# CYBLE_416045_02 register map
File version: 0.1
Registers are 32-bit, read-write, no defined reset value unless marked. A register's access mark holds for its fields unless they carry their own. Offsets are from the block's base; [hi:lo] are bit positions; 'fields as' and 'values as' point back to an identical list.

## IDAC
Base 0x00000000
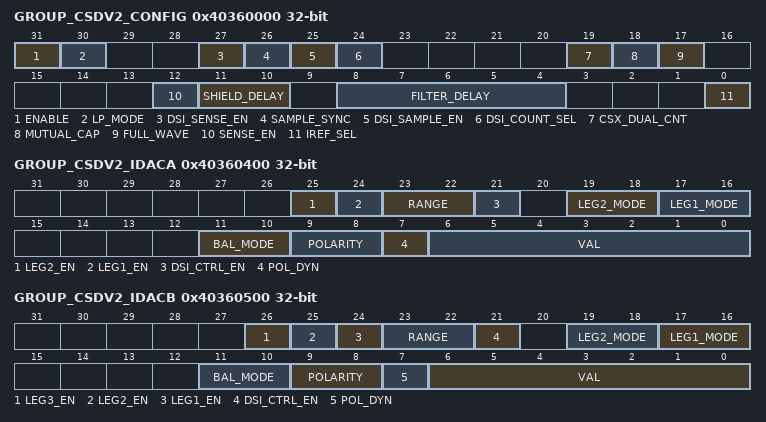
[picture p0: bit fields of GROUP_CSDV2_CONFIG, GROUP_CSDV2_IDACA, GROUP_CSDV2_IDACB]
0x40360000 GROUP_CSDV2_CONFIG — Configuration and Control
  [31] ENABLE — Master enable of the CSDv2 IP. Must be set to 1 for any CSDv2, ADC or IDAC operation to function.?When 0 all analog components will be off and all switches will be open.
  [30] LP_MODE — Select the power mode for the CSD components (REFGEN, AMBUF, CSDCMP, HSCMP):?0: High Power mode?1: Low Power mode
  [27] DSI_SENSE_EN — Enables the use of the dsi_sense_in input instead of the internally generated modulation signal to drive csd_sense and csd_shield signals.
  [26] SAMPLE_SYNC — Enables double synchronizing of sample input from DSI (only relevant when DSI_SAMPLE_EN=1).
  [25] DSI_SAMPLE_EN — Enables the use of the dsi_sample_in input instead of the comparator output to strobe COUNTER.
  [24] DSI_COUNT_SEL — Select what to output on the dsi_count bus.
    0=CSD_RESULT (depending on the dsi_count_val_sel input either output RESULT_VAL1.VALUE (0) or RESULT_VAL2.VALUE (1) on the dsi_count bus. Note that dsi_count_val_sel is not synchronized, i.e. it controls the mux combinatorially.); 1=ADC_RESULT (output ADC_RES.VIN_CNT on the dsi_count bus)
  [19] CSX_DUAL_CNT — Enable the use of two counters for MUTUAL cap sensing mode (CSX), do not use when MUTUAL_CAP=0
    0=ONE (Use one counter for both phases (source and sink).); 1=TWO (Use two counters, separate count for when csd_sense is high and when csd_sense is low.)
  [18] MUTUAL_CAP — Enables mutual cap sensing mode
    0=SELFCAP (Self-cap mode (configure sense line as CSD_SENSE)); 1=MUTUALCAP (Mutual-cap mode (configure Tx line as CSD_SENSE, inverted Tx line as CSD_SHIELD and Rx Line as AMUXA). In this mode the polarity bit of the IDAC is controlled by csd_sense.)
  [17] FULL_WAVE — Enables full wave cap sensing mode
    0=HALFWAVE (Half Wave mode (normal).?In this mode the comparator always trips in the same direction (positive or negative edge) and the same Vref, i.e. no polarity change.); 1=FULLWAVE (Full Wave mode.?In this mode the comparator trips in opposite direction and with different Vref in each phase, i.e. the polarity flips.)
  [12] SENSE_EN — Enables the sense modulator output. ?0: all switches, static or dynamic, are open and IDAC in CSD mode is off?1: switches and IDAC can be closed/on as per MMIO setting and CSD sequencer.
  [11:10] SHIELD_DELAY — Selects the delay by which csd_shield is delayed relative to csd_sense.
    0=OFF (Delay line is off, csd_shield=csd_sense); 1=D5NS (Introduces a 5ns delay (typ)); 2=D10NS (Introduces a 10ns delay (typ)); 3=D20NS (Introduces a 20ns delay (typ))
  [8:4] FILTER_DELAY — This value determines the number of cycles that the digital filter makes the CSDCMP output ignored while the counter counts and IDAC is on. ?When set to 0 the digital filter is off. When set to any other value the ignoring will last for FILTER_DELAY clk_csd cycles after the start of each measurement and from the first comparator trip to the end of each measurement.
  [0] IREF_SEL — Select Iref supply.
    0=IREF_SRSS (select SRSS Iref (default)); 1=IREF_PASS (select PASS.AREF Iref, only available if PASS IP is on the chip.)
0x40360400 GROUP_CSDV2_IDACA — IDACA Configuration
  [25] LEG2_EN — output enable for leg 2 to CSDBUSA
  [24] LEG1_EN — output enable for leg 1 to CSDBUSA
  [23:22] RANGE — IDAC multiplier
    0=IDAC_LO (1 LSB = 37.5 nA); 1=IDAC_MED (1 LSB = 300 nA); 2=IDAC_HI (1 LSB = 2400 nA)
  [21] DSI_CTRL_EN — Mix DSI inputs with MMIO controls or not (before getting mixed with CSD controls if enabled).?0: no DSI control ? IDACA_POLARITY = IDACA.POLARITY ? IDACA_LEG1_EN = IDACA.LEG1_EN ? IDACA_LEG2_EN = IDACA.LEG2_EN ?1: Mix MMIO with DSI control? IDACA_POLARITY = IDACA.POLARITY EXOR dsi_idaca_pol? IDACA_LEG1_EN = IDACA.LEG1_EN AND dsi_idaca_leg1_en ? IDACA_LEG2_EN = IDACA.LEG2_EN AND dsi_idaca_leg2_en
  [19:18] LEG2_MODE — Controls the usage mode of LEG2
    0=GP_STATIC (General Purpose static mode: LEG2 is controlled by MMIO and optionally mixed with DSI (see DSI_CTRL_EN). No shunting is used, this saves power when off but also any on/off switching will take longer.); 1=GP (General Purpose dynamic mode: LEG2 is controlled by MMIO and optionally mixed with DSI (see DSI_CTRL_EN). Shunting is used, so on/off switching is faster, but power is wasted when the leg is disabled.); 2=CSD_STATIC (CSD static mode: LEG2 can only be on when the CSD Sequencer is in the Sample_init or Sample_norm state. In those states LEG2 is controlled by LEG2_EN, csd_sense and the CSD configuration. Polarity is controlled by the CSD configuration and operation. In addition leg2 enable and polarity can optionally be mixed with DSI (see DSI_CTRL_EN). No shunting is used, this saves power when off but also any on/off switching will take longer.); 3=CSD (CSD dynamic mode: LEG2 can only be on when the CSD Sequencer is in the Sample_init or Sample_norm state. In those states LEG2 is controlled by LEG2_EN, the CSD configuration, csd_sense and the flopped CSDCMP output (CSDCMP_OUT_FF). In addition leg2 enable can optionally be mixed with DSI (see DSI_CTRL_EN). Shunting is used, so on/off switching is faster, but power is wasted when the leg is disabled.)
  [17:16] LEG1_MODE — Controls the usage mode of LEG1 and the Polarity bit
    0=GP_STATIC (General Purpose static mode: LEG1 and POLARITY are controlled by MMIO and optionally mixed with DSI (see DSI_CTRL_EN). No shunting is used, this saves power when off but also any on/off switching will take longer.); 1=GP (General Purpose dynamic mode: LEG1 and POLARITY are controlled by MMIO and optionally mixed with DSI (see DSI_CTRL_EN). Shunting is used, so on/off switching is faster, but power is wasted when the leg is disabled.); 2=CSD_STATIC (CSD static mode: LEG1 can only be on when the CSD Sequencer is in the Sample_init or Sample_norm state. In those states LEG1 is controlled by LEG1_EN, csd_sense and the CSD configuration. Polarity is controlled by the CSD configuration and operation. In addition leg1 enable and polarity can optionally be mixed with DSI (see DSI_CTRL_EN). No shunting is used, this saves power when off but also any on/off switching will take longer.); 3=CSD (CSD dynamic mode: LEG1 can only be on when the CSD Sequencer is in the Sample_init or Sample_norm state. In thoses states LEG1 is controlled by LEG1_EN, the CSD configuration, csd_sense and the flopped CSDCMP output (CSDCMP_OUT_FF). Polarity is controlled by the CSD configuration and operation. In addition leg1 enable and polarity can optionally be mixed with DSI (see DSI_CTRL_EN). Shunting is used, so on/off switching is faster, but power is wasted when the leg is disabled.)
  [11:10] BAL_MODE — Balancing mode: only applies to legs configured as CSD.
    0=FULL (enabled from start of Phi2 until disabled by CSDCMP. Intended usage: legacy CSD for balancing over a full csd_sense period (non-overlap should be turned off)); 1=PHI1 (enabled from start of Phi1 and disabled by CSDCMP or at end of Phi1. Enables dual IDAC CSX or Full-Wave, one for sourcing and the other for sinking.); 2=PHI2 (enabled from start of Phi2 and disabled by CSDCMP or at end of Phi2. Intended usage: CSD Low EMI or dual IDAC CSX or Full-Wave.); 3=PHI1_2 (enabled from start of both Phi1 and Phi2 and disabled by CSDCMP or at end of Phi1 or Phi2 (if non-overlap enabled). Intended usage: single IDAC CSX, or Full-Wave.)
  [9:8] POLARITY — Selects the polarity of the IDAC (sensing operation). Normally the actual polarity depends on this bit, optionally mixed with DSI (see DSI_CTRL_EN) and if LEG1_MODE==CSD also mixed with the CSD configuration and operation. However in mutual cap mode with one IDAC (config.mutual_cap=1 & config.csx_dual_idac=0) the polarity of the IDAC is controlled by csd_sense.
    0=VSSA_SRC (Normal: switch between Vssa and Cmod. For non-CSD application, IDAC will source current.); 1=VDDA_SNK (Inverted: switch between Vdda and Cmod. For non-CSD application, IDAC will sink current.); 2=SENSE (The polarity of the IDAC will follow the csd_sense signal (POL_DYN bit should be set too). The intended usage is for CSX using a single IDAC.); 3=SENSE_INV (The polarity of the IDAC will follow the inverted csd_sense signal (POL_DYN bit should be set too). The intended usage is for CSX using a single IDAC.)
  [7] POL_DYN — Polarity is dynamic, this bit does not influence the logic in the SoftIP, it only goes to the HardIP.
    0=STATIC (Static polarity. Polarity is expected to be stable, so to save power this avoids the shunting of the unused polarity, at the expense of response time.); 1=DYNAMIC (Dynamic polarity. Polarity is expected to change frequently (e.g. invert after every csd_sense phase), so to improve response time this keeps the shunt of the unused polarity on at the expense of power.)
  [6:0] VAL — Current value setting for this IDAC (7 bits).
0x40360500 GROUP_CSDV2_IDACB — IDACB Configuration
  [26] LEG3_EN — output enable for leg3 to CSDBUSC, only allowed when RANGE = IDAC_LO. When this bit is set both other legs should be off.?Note that leg3 can only be used for ADC mode, not GP mode. Which means that leg3 can only be on when the ADC Sequencer is in the ADC_measure or Calib_measure state. In those states leg3 is controlled by the ADC configuration and the HSCMP output. In addition this leg3 enable bit can optionally be mixed with DSI (see DSI_CTRL_EN).?When LEG3_EN=1 also the IDACB polarity is controlled by the ADC sequencer.
  [25] LEG2_EN — output enable for leg 2 to CSDBUSB or CSDBUSA
  [24] LEG1_EN — output enable for leg 1 to CSDBUSB or CSDBUSA
  [23:22] RANGE — IDAC multiplier
    values as GROUP_CSDV2_IDACA.RANGE
  [21] DSI_CTRL_EN — Mix DSI inputs with MMIO controls or not (before getting mixed with CSD controls if enabled)?0: no DSI control? IDACB_POLARITY = IDACB.POLARITY ? IDACB_LEG1_EN = IDACB.LEG1_EN ? IDACB_LEG2_EN = IDACB.LEG2_EN ? IDACB_LEG3_EN = IDACB.LEG3_EN ?1: Mix MMIO with DSI control? IDACB_POLARITY = IDACB.POLARITY EXOR dsi_idacb_pol? IDACB_LEG1_EN = IDACB.LEG1_EN AND dsi_idacb_leg1_en ? IDACB_LEG2_EN = IDACB.LEG2_EN AND dsi_idacb_leg2_en ? IDACB_LEG3_EN = IDACB.LEG3_EN AND dsi_idacb_leg3_en
  [19:18] LEG2_MODE — Controls the usage mode of LEG2
    0=GP_STATIC (same as corresponding IDACA.LEG2_MODE); 1=GP (same as corresponding IDACA.LEG2_MODE); 2=CSD_STATIC (same as corresponding IDACA.LEG2_MODE); 3=CSD (same as corresponding IDACA.LEG2_MODE)
  [17:16] LEG1_MODE — Controls the usage mode of LEG1 and the Polarity bit
    0=GP_STATIC (same as corresponding IDACA.LEG1_MODE); 1=GP (same as corresponding IDACA.LEG1_MODE); 2=CSD_STATIC (same as corresponding IDACA.LEG1_MODE); 3=CSD (same as corresponding IDACA.LEG1_MODE)
  [11:10] BAL_MODE — same as corresponding IDACA Balancing mode
    0=FULL (same as corresponding IDACA Balancing mode); 1=PHI1 (same as corresponding IDACA Balancing mode); 2=PHI2 (same as corresponding IDACA Balancing mode); 3=PHI1_2 (same as corresponding IDACA Balancing mode)
  [9:8] POLARITY — Selects the polarity of the IDAC (sensing operation). Normally the actual polarity depends on this bit, optionally mixed with DSI (see DSI_CTRL_EN) and if LEG1_EN==1 and LEG1_MODE==CSD also mixed with the CSD configuration and operation. In mutual cap mode however (see config.mutual_cap) the polarity of the IDAC is controlled by csd_sense. If LEG3_EN=1 (the other two legs must be off) then the ADC sequencer controls the IDACB polarity, optionally mixed with DSI.
    values as GROUP_CSDV2_IDACA.POLARITY
  [7] POL_DYN — Polarity is dynamic, this bit does not influence the logic in the SoftIP, it only goes to the HardIP.
    values as GROUP_CSDV2_IDACA.POL_DYN
  [6:0] VAL — Current value setting for this IDAC (7 bits).
